VERSION "HIPBNYYYYYYYYYYYYYYYYYYYYYYYYYYYYYYYYYYYYY/4/%%%/4/'%**4YYY///"

NS_ :

BS_:

BU_: ME_AWS_CANA
VAL_TABLE_ Driver_mode 15 "Invalid value" 14 "Description for the value '0xE'" 13 "Description for the value '0xD'" 12 "Description for the value '0xC'" 11 "Description for the value '0xB'" 10 "Description for the value '0xA'" 9 "Description for the value '0x9'" 8 "Description for the value '0x8'" 7 "Description for the value '0x7'" 6 "Description for the value '0x6'" 5 "Description for the value '0x5'" 4 "Description for the value '0x4'" 3 "Description for the value '0x3'" 2 "Way to/from work drive" 1 "Personal drive" 0 "Work drive" ;
VAL_TABLE_ Driver_assignment 7 "invalid value" 6 "Description for the value '0x6'" 5 "Description for the value '0x5'" 4 "Description for the value '0x4'" 3 "Description for the value '0x3'" 2 "assigned" 1 "in process" 0 "not assigned" ;
VAL_TABLE_ Validity 1 "invalid" 0 "valid" ;
VAL_TABLE_ Running_mode 15 "Invalid value" 14 "Description for the value '0xE'" 13 "Description for the value '0xD'" 12 "Description for the value '0xC'" 11 "Description for the value '0xB'" 10 "Description for the value '0xA'" 9 "Description for the value '0x9'" 8 "Description for the value '0x8'" 7 "Description for the value '0x7'" 6 "Description for the value '0x6'" 5 "Description for the value '0x5'" 4 "Description for the value '0x4'" 3 "Normal mode" 2 "Keep power on mode" 1 "Airplane mode" 0 "Pilot mode" ;
VAL_TABLE_ Present_app 15 "Invalid value" 14 "Description for the value '0xE'" 13 "Description for the value '0xD'" 12 "Description for the value '0xC'" 11 "Description for the value '0xB'" 10 "Description for the value '0xA'" 9 "Description for the value '0x9'" 8 "Description for the value '0x8'" 7 "Description for the value '0x7'" 6 "Description for the value '0x6'" 5 "Description for the value '0x5'" 4 "Description for the value '0x4'" 3 "Description for the value '0x3'" 2 "Description for the value '0x2'" 1 "Description for the value '0x1'" 0 "Description for the value '0x0'" ;

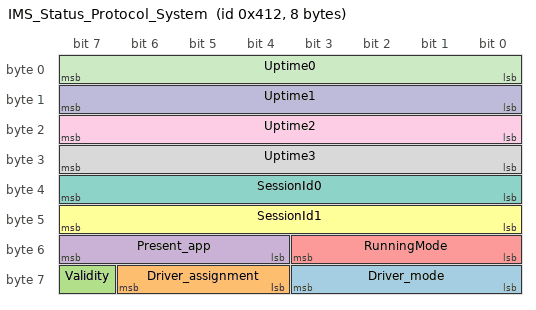
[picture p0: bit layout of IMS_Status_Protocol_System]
BO_ 1042 IMS_Status_Protocol_System: 8 Vector__XXX
 SG_ Driver_mode : 56|4@1+ (1,0) [0|15] "" Vector__XXX
 SG_ Driver_assignment : 60|3@1+ (1,0) [0|7] "" Vector__XXX
 SG_ Validity : 63|1@1+ (1,0) [0|1] "" Vector__XXX
 SG_ Present_app : 52|4@1+ (1,0) [0|15] "" Vector__XXX
 SG_ RunningMode : 48|4@1+ (1,0) [0|15] "" Vector__XXX
 SG_ SessionId1 : 40|8@1+ (1,0) [0|255] "" Vector__XXX
 SG_ SessionId0 : 32|8@1+ (1,0) [0|255] "" Vector__XXX
 SG_ Uptime3 : 24|8@1+ (1,0) [0|255] "" Vector__XXX
 SG_ Uptime2 : 16|8@1+ (1,0) [0|255] "" Vector__XXX
 SG_ Uptime1 : 8|8@1+ (1,0) [0|255] "" Vector__XXX
 SG_ Uptime0 : 0|8@1+ (1,0) [0|255] "" Vector__XXX

BA_DEF_  "BusType" STRING ;
BA_DEF_DEF_  "BusType" "CAN";
VAL_ 1042 Driver_mode 15 "Invalid value" 14 "Description for the value '0xE'" 13 "Description for the value '0xD'" 12 "Description for the value '0xC'" 11 "Description for the value '0xB'" 10 "Description for the value '0xA'" 9 "Description for the value '0x9'" 8 "Description for the value '0x8'" 7 "Description for the value '0x7'" 6 "Description for the value '0x6'" 5 "Description for the value '0x5'" 4 "Description for the value '0x4'" 3 "Description for the value '0x3'" 2 "Way to/from work drive" 1 "Personal drive" 0 "Work drive" ;
VAL_ 1042 Driver_assignment 7 "invalid value" 6 "Description for the value '0x6'" 5 "Description for the value '0x5'" 4 "Description for the value '0x4'" 3 "Description for the value '0x3'" 2 "assigned" 1 "in process" 0 "not assigned" ;
VAL_ 1042 Validity 1 "invalid" 0 "valid" ;
VAL_ 1042 Present_app 15 "Invalid value" 14 "Description for the value '0xE'" 13 "Description for the value '0xD'" 12 "Description for the value '0xC'" 11 "Description for the value '0xB'" 10 "Description for the value '0xA'" 9 "Description for the value '0x9'" 8 "Description for the value '0x8'" 7 "Description for the value '0x7'" 6 "Description for the value '0x6'" 5 "Description for the value '0x5'" 4 "Description for the value '0x4'" 3 "Description for the value '0x3'" 2 "Description for the value '0x2'" 1 "Description for the value '0x1'" 0 "Description for the value '0x0'" ;
VAL_ 1042 RunningMode 15 "Invalid value" 14 "Description for the value '0xE'" 13 "Description for the value '0xD'" 12 "Description for the value '0xC'" 11 "Description for the value '0xB'" 10 "Description for the value '0xA'" 9 "Description for the value '0x9'" 8 "Description for the value '0x8'" 7 "Description for the value '0x7'" 6 "Description for the value '0x6'" 5 "Description for the value '0x5'" 4 "Description for the value '0x4'" 3 "Normal mode" 2 "Keep power on mode" 1 "Airplane mode" 0 "Pilot mode" ;
